# ESP32 register map
Vendor: ESPRESSIF SYSTEMS (SHANGHAI) CO., LTD.; Series: ESP32 Series; File version: 17
CPU: Xtensa LX6 r0p0, little endian, no MPU, FPU, 0 interrupt priority bits
Address unit: 32 bits
Registers are 32-bit, read-write, reset 0x0 unless marked. A register's access mark holds for its fields unless they carry their own. Offsets are from the block's base; [hi:lo] are bit positions; {n}, {i} and the like mark numbered series.

## TIMG0 — Timer Group 0
Base 0x3FF5F000
Same registers: TIMG1 0x3FF60000
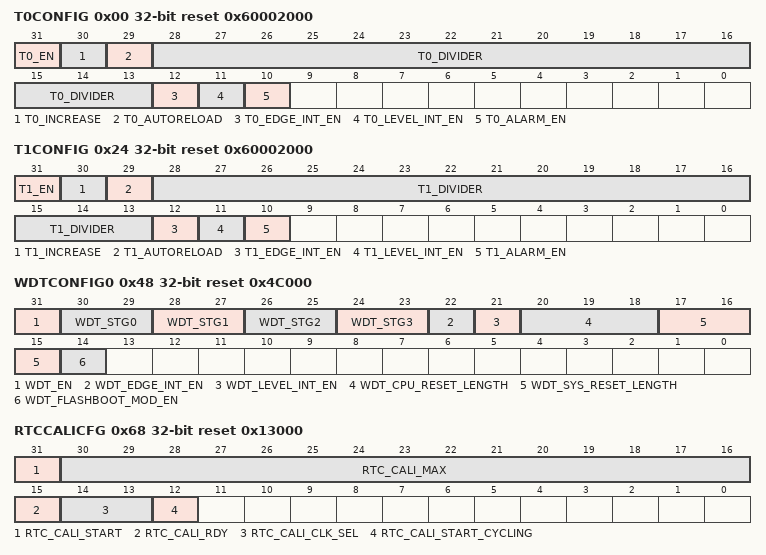
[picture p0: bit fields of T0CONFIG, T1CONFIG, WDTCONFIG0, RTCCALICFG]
0x00 T0CONFIG reset 0x60002000
  [31] T0_EN — When set timer 0 time-base counter is enabled
  [30] T0_INCREASE — When set timer 0 time-base counter increment. When cleared timer 0 time-base counter decrement.
  [29] T0_AUTORELOAD — When set timer 0 auto-reload at alarming is enabled
  [28:13] T0_DIVIDER — Timer 0 clock (T0_clk) prescale value.
  [12] T0_EDGE_INT_EN — When set edge type interrupt will be generated during alarm
  [11] T0_LEVEL_INT_EN — When set level type interrupt will be generated during alarm
  [10] T0_ALARM_EN — When set alarm is enabled
0x04 T0LO ro
  [31:0] T0_LO — Register to store timer 0 time-base counter current value lower 32 bits.
0x08 T0HI ro
  [31:0] T0_HI — Register to store timer 0 time-base counter current value higher 32 bits.
0x0C T0UPDATE wo
  [31:0] T0_UPDATE — Write any value will trigger a timer 0 time-base counter value update (timer 0 current value will be stored in registers above)
0x10 T0ALARMLO
  [31:0] T0_ALARM_LO — Timer 0 time-base counter value lower 32 bits that will trigger the alarm
0x14 T0ALARMHI
  [31:0] T0_ALARM_HI — Timer 0 time-base counter value higher 32 bits that will trigger the alarm
0x18 T0LOADLO
  [31:0] T0_LOAD_LO — Lower 32 bits of the value that will load into timer 0 time-base counter
0x1C T0LOADHI
  [31:0] T0_LOAD_HI — higher 32 bits of the value that will load into timer 0 time-base counter
0x20 T0LOAD wo
  [31:0] T0_LOAD — Write any value will trigger timer 0 time-base counter reload
0x24 T1CONFIG reset 0x60002000
  [31] T1_EN — When set timer 1 time-base counter is enabled
  [30] T1_INCREASE — When set timer 1 time-base counter increment. When cleared timer 1 time-base counter decrement.
  [29] T1_AUTORELOAD — When set timer 1 auto-reload at alarming is enabled
  [28:13] T1_DIVIDER — Timer 1 clock (T1_clk) prescale value.
  [12] T1_EDGE_INT_EN — When set edge type interrupt will be generated during alarm
  [11] T1_LEVEL_INT_EN — When set level type interrupt will be generated during alarm
  [10] T1_ALARM_EN — When set alarm is enabled
0x28 T1LO ro
  [31:0] T1_LO — Register to store timer 1 time-base counter current value lower 32 bits.
0x2C T1HI ro
  [31:0] T1_HI — Register to store timer 1 time-base counter current value higher 32 bits.
0x30 T1UPDATE wo
  [31:0] T1_UPDATE — Write any value will trigger a timer 1 time-base counter value update (timer 1 current value will be stored in registers above)
0x34 T1ALARMLO
  [31:0] T1_ALARM_LO — Timer 1 time-base counter value lower 32 bits that will trigger the alarm
0x38 T1ALARMHI
  [31:0] T1_ALARM_HI — Timer 1 time-base counter value higher 32 bits that will trigger the alarm
0x3C T1LOADLO
  [31:0] T1_LOAD_LO — Lower 32 bits of the value that will load into timer 1 time-base counter
0x40 T1LOADHI
  [31:0] T1_LOAD_HI — higher 32 bits of the value that will load into timer 1 time-base counter
0x44 T1LOAD wo
  [31:0] T1_LOAD — Write any value will trigger timer 1 time-base counter reload
0x48 WDTCONFIG0 reset 0x4C000
  [31] WDT_EN — When set SWDT is enabled
  [30-2n:29-2n] WDT_STG{n} (n=0..3) — Stage {n} configuration. 0: off 1: interrupt 2: reset CPU 3: reset system
  [22] WDT_EDGE_INT_EN — When set edge type interrupt generation is enabled
  [21] WDT_LEVEL_INT_EN — When set level type interrupt generation is enabled
  [20:18] WDT_CPU_RESET_LENGTH — length of CPU reset selection. 0: 100ns 1: 200ns 2: 300ns 3: 400ns 4: 500ns 5: 800ns 6: 1.6us 7: 3.2us
  [17:15] WDT_SYS_RESET_LENGTH — length of system reset selection. 0: 100ns 1: 200ns 2: 300ns 3: 400ns 4: 500ns 5: 800ns 6: 1.6us 7: 3.2us
  [14] WDT_FLASHBOOT_MOD_EN — When set flash boot protection is enabled
0x4C WDTCONFIG1 reset 0x10000
  [31:16] WDT_CLK_PRESCALE — SWDT clock prescale value. Period = 12.5ns * value stored in this register
0x50 WDTCONFIG2 reset 0x18CBA80
  [31:0] WDT_STG0_HOLD — Stage 0 timeout value in SWDT clock cycles
0x54 WDTCONFIG3 reset 0x7FFFFFF
  [31:0] WDT_STG1_HOLD — Stage 1 timeout value in SWDT clock cycles
0x58 WDTCONFIG4 reset 0xFFFFF
  [31:0] WDT_STG2_HOLD — Stage 2 timeout value in SWDT clock cycles
0x5C WDTCONFIG5 reset 0xFFFFF
  [31:0] WDT_STG3_HOLD — Stage 3 timeout value in SWDT clock cycles
0x60 WDTFEED wo
  [31:0] WDT_FEED — Write any value will feed SWDT
0x64 WDTWPROTECT reset 0x50D83AA1
  [31:0] WDT_WKEY — If change its value from default then write protection is on.
0x68 RTCCALICFG access per field reset 0x13000
  [31] RTC_CALI_START rw, [30:16] RTC_CALI_MAX rw, [15] RTC_CALI_RDY ro, [14:13] RTC_CALI_CLK_SEL rw, [12] RTC_CALI_START_CYCLING rw
0x6C RTCCALICFG1 ro
  [31:7] RTC_CALI_VALUE
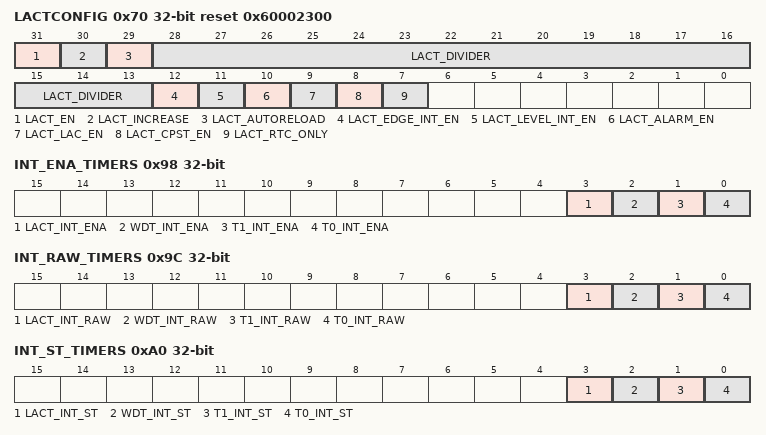
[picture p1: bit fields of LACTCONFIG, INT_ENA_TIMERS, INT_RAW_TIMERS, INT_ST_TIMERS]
0x70 LACTCONFIG reset 0x60002300
  [31] LACT_EN, [30] LACT_INCREASE, [29] LACT_AUTORELOAD, [28:13] LACT_DIVIDER, [12] LACT_EDGE_INT_EN, [11] LACT_LEVEL_INT_EN, [10] LACT_ALARM_EN, [9] LACT_LAC_EN, [8] LACT_CPST_EN, [7] LACT_RTC_ONLY
0x74 LACTRTC
  [31:6] LACT_RTC_STEP_LEN
0x78 LACTLO ro
  [31:0] LACT_LO
0x7C LACTHI ro
  [31:0] LACT_HI
0x80 LACTUPDATE wo
  [31:0] LACT_UPDATE
0x84 LACTALARMLO
  [31:0] LACT_ALARM_LO
0x88 LACTALARMHI
  [31:0] LACT_ALARM_HI
0x8C LACTLOADLO
  [31:0] LACT_LOAD_LO
0x90 LACTLOADHI
  [31:0] LACT_LOAD_HI
0x94 LACTLOAD wo
  [31:0] LACT_LOAD
0x98 INT_ENA_TIMERS
  [3] LACT_INT_ENA
  [2] WDT_INT_ENA — Interrupt when an interrupt stage timeout
  [1] T1_INT_ENA — interrupt when timer1 alarm
  [0] T0_INT_ENA — interrupt when timer0 alarm
0x9C INT_RAW_TIMERS ro
  [3] LACT_INT_RAW
  [2] WDT_INT_RAW — Interrupt when an interrupt stage timeout
  [1] T1_INT_RAW — interrupt when timer1 alarm
  [0] T0_INT_RAW — interrupt when timer0 alarm
0xA0 INT_ST_TIMERS ro
  [3] LACT_INT_ST
  [2] WDT_INT_ST — Interrupt when an interrupt stage timeout
  [1] T1_INT_ST — interrupt when timer1 alarm
  [0] T0_INT_ST — interrupt when timer0 alarm
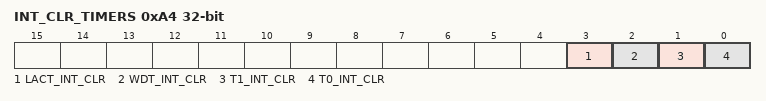
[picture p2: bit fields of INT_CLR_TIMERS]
0xA4 INT_CLR_TIMERS wo
  [3] LACT_INT_CLR
  [2] WDT_INT_CLR — Interrupt when an interrupt stage timeout
  [1] T1_INT_CLR — interrupt when timer1 alarm
  [0] T0_INT_CLR — interrupt when timer0 alarm
0xF8 NTIMERS_DATE reset 0x1604290
  [27:0] NTIMERS_DATE — Version of this regfile
0xFC TIMGCLK
  [31] CLK_EN — Force clock enable for this regfile
